# apollo4b register map
Vendor: Ambiq Micro; Series: Apollo; File version: 1.0
CPU: CM4 r1p0, little endian, MPU, FPU, I-cache, D-cache, VTOR, ITCM, DTCM, 3 interrupt priority bits, 0 interrupts
Registers are 32-bit, read-write, reset 0x0 unless marked. A register's access mark holds for its fields unless they carry their own. Offsets are from the block's base; [hi:lo] are bit positions; {n}, {i} and the like mark numbered series; 'fields as' and 'values as' point back to an identical list.

## GPIO (part 4 of 4) — General Purpose IO
Base 0x40010000
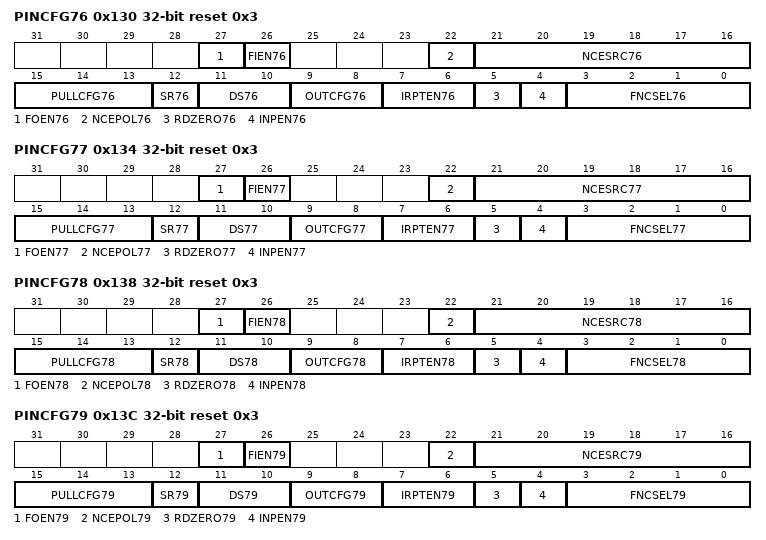
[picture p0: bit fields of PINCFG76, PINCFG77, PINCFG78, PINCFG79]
0x130 PINCFG76 reset 0x3 — Controls the operation of GPIO pin 76.
  [27] FOEN76 — Force output enable active regardless of function selected. Otherwise the selected function will enable the output only when needed
  [26] FIEN76 — Force input enable active regardless of function selected. Otherwise the selected function will enable the input only when needed
  [22] NCEPOL76 — Polarity select for NCE for GPIO 76
    0=LOW (Polarity is active low); 1=HIGH (Polarity is active high)
  [21:16] NCESRC76 — IOMSTR/MSPI N Chip Select 76, DISP control signals DE, CSX, and CS. Polarity is determined by CE_POLARITY field
    {v}=IOM0CE{v} (IOM 0 NCE {v} module) (v=0..3); {v}=IOM1CE{v-4} (IOM 1 NCE {v-4} module) (v=4..7); {v}=IOM2CE{v-8} (IOM 2 NCE {v-8} module) (v=8..11); {v}=IOM3CE{v-12} (IOM 3 NCE {v-12} module) (v=12..15); {v}=IOM4CE{v-16} (IOM 4 NCE {v-16} module) (v=16..19); {v}=IOM5CE{v-20} (IOM 5 NCE {v-20} module) (v=20..23); {v}=IOM6CE{v-24} (IOM 6 NCE {v-24} module) (v=24..27); {v}=IOM7CE{v-28} (IOM 7 NCE {v-28} module) (v=28..31); 32=MSPI0CEN0 (MSPI 0 NCE 0 module); 33=MSPI0CEN1 (MSPI 0 NCE 1 module); 34=MSPI1CEN0 (MSPI 1 NCE 0 module); 35=MSPI1CEN1 (MSPI 1 NCE 1 module); 36=MSPI2CEN0 (MSPI 2 NCE 0 module); 37=MSPI2CEN1 (MSPI 2 NCE 1 module); 38=DC_DPI_DE (DC DPI DE module); 39=DISP_CONT_CSX (DISP CONT CSX module); 40=DC_SPI_CS_N (DC SPI CS_N module); 41=DC_QSPI_CS_N (DC QSPI CS_N module); 42=DC_RESX (DC module RESX)
  [15:13] PULLCFG76 — Pullup/Pulldown configuration for GPIO 76
    0=DIS (No pullup or pulldown selected); 1=PD50K (50K Pulldown selected); 2=PU15K (1.5K Pullup selected); 3=PU6K (6K Pullup selected); 4=PU12K (12K Pullup selected); 5=PU24K (24K Pullup selected); 6=PU50K (50K Pullup selected); 7=PU100K (100K Pullup selected)
  [12] SR76 — Configure the slew rate
  [11:10] DS76 — Drive strength selection for GPIO 76
    0=0P1X (0.1x output driver selected); 1=0P5X (0.5x output driver selected); 2=0P75X (0.75x output driver selected); 3=1P0X (1.0x output driver selected)
  [9:8] OUTCFG76 — Pin IO mode selection for GPIO pin 76
    0=DIS (Output Disabled); 1=PUSHPULL (Output configured in push pull mode. Will drive 0 and 1 values on pin.); 2=OD (Output configured in open drain mode. Will only drive pin low, tristate otherwise.); 3=TS (Output configured in Tristate-able push pull mode. Will drive 0, 1 of HiZ on pin.)
  [7:6] IRPTEN76 — Interrupt enable for GPIO 76
    0=DIS (Interrupts are disabled for this GPIO); 1=INTFALL (Interrupts are enabled for falling edge transition on this GPIO); 2=INTRISE (Interrupts are enabled for rising edge transitions on this GPIO); 3=INTANY (Interrupts are enabled for any edge transition on this GPIO)
  [5] RDZERO76 — Return 0 for read data on GPIO 76
  [4] INPEN76 — Input enable for GPIO 76
  [3:0] FNCSEL76 — Function select for GPIO pin 76
    0=MSPI2_2 (MSPI Master 2 Interface Signal); 1=32KHzXT (32kHZ from analog); 2=DISP_QSPI_D2 (Display SPI Data2); 3=GPIO (General purpose I/O); 4=UART0RTS (UART Request to Send (RTS) (UART 0)); 5=DISP_D12 (Display Data 12); 6=CT76 (Timer/Counter input or output; Selection of direction is done via CTIMER register settings.); 7=NCE76 (IOMSTR/MSPI N Chip Select. Polarity is determined by CE_POLARITY field); 8=OBSBUS12 (Observation bus bit 12); 11=FPIO (Fast PIO)
0x134 PINCFG77 reset 0x3 — Controls the operation of GPIO pin 77.
  [27] FOEN77 — Force output enable active regardless of function selected. Otherwise the selected function will enable the output only when needed
  [26] FIEN77 — Force input enable active regardless of function selected. Otherwise the selected function will enable the input only when needed
  [22] NCEPOL77 — Polarity select for NCE for GPIO 77
    values as PINCFG76.NCEPOL76
  [21:16] NCESRC77 — IOMSTR/MSPI N Chip Select 77, DISP control signals DE, CSX, and CS. Polarity is determined by CE_POLARITY field
    values as PINCFG76.NCESRC76
  [15:13] PULLCFG77 — Pullup/Pulldown configuration for GPIO 77
    values as PINCFG76.PULLCFG76
  [12] SR77 — Configure the slew rate
  [11:10] DS77 — Drive strength selection for GPIO 77
    values as PINCFG76.DS76
  [9:8] OUTCFG77 — Pin IO mode selection for GPIO pin 77
    values as PINCFG76.OUTCFG76
  [7:6] IRPTEN77 — Interrupt enable for GPIO 77
    values as PINCFG76.IRPTEN76
  [5] RDZERO77 — Return 0 for read data on GPIO 77
  [4] INPEN77 — Input enable for GPIO 77
  [3:0] FNCSEL77 — Function select for GPIO pin 77
    0=MSPI2_3 (MSPI Master 2 Interface Signal); 2=DISP_QSPI_D3 (Display SPI Data3); 3=GPIO (General purpose I/O); 4=UART0CTS (UART Clear to Send (CTS) (UART 0)); 5=DISP_D13 (Display Data 13); 6=CT77 (Timer/Counter input or output; Selection of direction is done via CTIMER register settings.); 7=NCE77 (IOMSTR/MSPI N Chip Select. Polarity is determined by CE_POLARITY field); 8=OBSBUS13 (Observation bus bit 13); 11=FPIO (Fast PIO)
0x138 PINCFG78 reset 0x3 — Controls the operation of GPIO pin 78.
  [27] FOEN78 — Force output enable active regardless of function selected. Otherwise the selected function will enable the output only when needed
  [26] FIEN78 — Force input enable active regardless of function selected. Otherwise the selected function will enable the input only when needed
  [22] NCEPOL78 — Polarity select for NCE for GPIO 78
    values as PINCFG76.NCEPOL76
  [21:16] NCESRC78 — IOMSTR/MSPI N Chip Select 78, DISP control signals DE, CSX, and CS. Polarity is determined by CE_POLARITY field
    values as PINCFG76.NCESRC76
  [15:13] PULLCFG78 — Pullup/Pulldown configuration for GPIO 78
    values as PINCFG76.PULLCFG76
  [12] SR78 — Configure the slew rate
  [11:10] DS78 — Drive strength selection for GPIO 78
    values as PINCFG76.DS76
  [9:8] OUTCFG78 — Pin IO mode selection for GPIO pin 78
    values as PINCFG76.OUTCFG76
  [7:6] IRPTEN78 — Interrupt enable for GPIO 78
    values as PINCFG76.IRPTEN76
  [5] RDZERO78 — Return 0 for read data on GPIO 78
  [4] INPEN78 — Input enable for GPIO 78
  [3:0] FNCSEL78 — Function select for GPIO pin 78
    0=MSPI2_4 (MSPI Master 2 Interface Signal); 2=DISP_QSPI_SCK (Display SPI CLK); 3=GPIO (General purpose I/O); 4=UART0TX (UART transmit output (UART 0)); 5=DISP_D14 (Display Data 14); 6=CT78 (Timer/Counter input or output; Selection of direction is done via CTIMER register settings.); 7=NCE78 (IOMSTR/MSPI N Chip Select. Polarity is determined by CE_POLARITY field); 8=OBSBUS14 (Observation bus bit 14); 9=DISP_SPI_SCK (Display SPI Clock); 11=FPIO (Fast PIO)
0x13C PINCFG79 reset 0x3 — Controls the operation of GPIO pin 79.
  [27] FOEN79 — Force output enable active regardless of function selected. Otherwise the selected function will enable the output only when needed
  [26] FIEN79 — Force input enable active regardless of function selected. Otherwise the selected function will enable the input only when needed
  [22] NCEPOL79 — Polarity select for NCE for GPIO 79
    values as PINCFG76.NCEPOL76
  [21:16] NCESRC79 — IOMSTR/MSPI N Chip Select 79, DISP control signals DE, CSX, and CS. Polarity is determined by CE_POLARITY field
    values as PINCFG76.NCESRC76
  [15:13] PULLCFG79 — Pullup/Pulldown configuration for GPIO 79
    values as PINCFG76.PULLCFG76
  [12] SR79 — Configure the slew rate
  [11:10] DS79 — Drive strength selection for GPIO 79
    values as PINCFG76.DS76
  [9:8] OUTCFG79 — Pin IO mode selection for GPIO pin 79
    values as PINCFG76.OUTCFG76
  [7:6] IRPTEN79 — Interrupt enable for GPIO 79
    values as PINCFG76.IRPTEN76
  [5] RDZERO79 — Return 0 for read data on GPIO 79
  [4] INPEN79 — Input enable for GPIO 79
  [3:0] FNCSEL79 — Function select for GPIO pin 79
    0=MSPI2_5 (MSPI Master 2 Interface Signal); 2=SDIF_DAT4 (SD/SDIO/MMC Data4 pin); 3=GPIO (General purpose I/O); 4=SWO (Serial Wire Output); 5=DISP_VS (Display RGB VSYNC); 6=CT79 (Timer/Counter input or output; Selection of direction is done via CTIMER register settings.); 7=NCE79 (IOMSTR/MSPI N Chip Select. Polarity is determined by CE_POLARITY field); 8=OBSBUS15 (Observation bus bit 15); 9=DISP_SPI_SDI (Display SPI Data IN); 11=FPIO (Fast PIO)
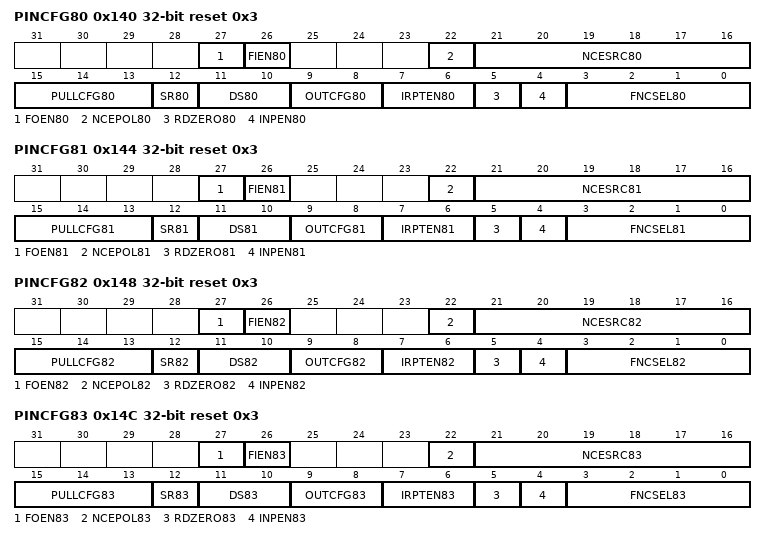
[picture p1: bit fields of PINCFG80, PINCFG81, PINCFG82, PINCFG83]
0x140 PINCFG80 reset 0x3 — Controls the operation of GPIO pin 80.
  [27] FOEN80 — Force output enable active regardless of function selected. Otherwise the selected function will enable the output only when needed
  [26] FIEN80 — Force input enable active regardless of function selected. Otherwise the selected function will enable the input only when needed
  [22] NCEPOL80 — Polarity select for NCE for GPIO 80
    values as PINCFG76.NCEPOL76
  [21:16] NCESRC80 — IOMSTR/MSPI N Chip Select 80, DISP control signals DE, CSX, and CS. Polarity is determined by CE_POLARITY field
    values as PINCFG76.NCESRC76
  [15:13] PULLCFG80 — Pullup/Pulldown configuration for GPIO 80
    values as PINCFG76.PULLCFG76
  [12] SR80 — Configure the slew rate
  [11:10] DS80 — Drive strength selection for GPIO 80
    values as PINCFG76.DS76
  [9:8] OUTCFG80 — Pin IO mode selection for GPIO pin 80
    values as PINCFG76.OUTCFG76
  [7:6] IRPTEN80 — Interrupt enable for GPIO 80
    values as PINCFG76.IRPTEN76
  [5] RDZERO80 — Return 0 for read data on GPIO 80
  [4] INPEN80 — Input enable for GPIO 80
  [3:0] FNCSEL80 — Function select for GPIO pin 80
    0=MSPI2_6 (MSPI Master 2 Interface Signal); 1=CLKOUT (Oscillator output clock); 2=SDIF_DAT5 (SD/SDIO/MMC Data5 pin); 3=GPIO (General purpose I/O); 4=SWTRACE0 (Serial Wire Debug Trace Output 0); 5=DISP_HS (Display RGB HSYNC); 6=CT80 (Timer/Counter input or output; Selection of direction is done via CTIMER register settings.); 7=NCE80 (IOMSTR/MSPI N Chip Select. Polarity is determined by CE_POLARITY field); 8=OBSBUS0 (Observation bus bit 0); 11=FPIO (Fast PIO)
0x144 PINCFG81 reset 0x3 — Controls the operation of GPIO pin 81.
  [27] FOEN81 — Force output enable active regardless of function selected. Otherwise the selected function will enable the output only when needed
  [26] FIEN81 — Force input enable active regardless of function selected. Otherwise the selected function will enable the input only when needed
  [22] NCEPOL81 — Polarity select for NCE for GPIO 81
    values as PINCFG76.NCEPOL76
  [21:16] NCESRC81 — IOMSTR/MSPI N Chip Select 81, DISP control signals DE, CSX, and CS. Polarity is determined by CE_POLARITY field
    values as PINCFG76.NCESRC76
  [15:13] PULLCFG81 — Pullup/Pulldown configuration for GPIO 81
    values as PINCFG76.PULLCFG76
  [12] SR81 — Configure the slew rate
  [11:10] DS81 — Drive strength selection for GPIO 81
    values as PINCFG76.DS76
  [9:8] OUTCFG81 — Pin IO mode selection for GPIO pin 81
    values as PINCFG76.OUTCFG76
  [7:6] IRPTEN81 — Interrupt enable for GPIO 81
    values as PINCFG76.IRPTEN76
  [5] RDZERO81 — Return 0 for read data on GPIO 81
  [4] INPEN81 — Input enable for GPIO 81
  [3:0] FNCSEL81 — Function select for GPIO pin 81
    0=MSPI2_7 (MSPI Master 2 Interface Signal); 1=CLKOUT (Oscillator output clock); 2=SDIF_DAT6 (SD/SDIO/MMC Data6 pin); 3=GPIO (General purpose I/O); 4=SWTRACE1 (Serial Wire Debug Trace Output 1); 5=DISP_DE (Display RGB Data Enable); 6=CT81 (Timer/Counter input or output; Selection of direction is done via CTIMER register settings.); 7=NCE81 (IOMSTR/MSPI N Chip Select. Polarity is determined by CE_POLARITY field); 8=OBSBUS1 (Observation bus bit 1); 11=FPIO (Fast PIO)
0x148 PINCFG82 reset 0x3 — Controls the operation of GPIO pin 82.
  [27] FOEN82 — Force output enable active regardless of function selected. Otherwise the selected function will enable the output only when needed
  [26] FIEN82 — Force input enable active regardless of function selected. Otherwise the selected function will enable the input only when needed
  [22] NCEPOL82 — Polarity select for NCE for GPIO 82
    values as PINCFG76.NCEPOL76
  [21:16] NCESRC82 — IOMSTR/MSPI N Chip Select 82, DISP control signals DE, CSX, and CS. Polarity is determined by CE_POLARITY field
    values as PINCFG76.NCESRC76
  [15:13] PULLCFG82 — Pullup/Pulldown configuration for GPIO 82
    values as PINCFG76.PULLCFG76
  [12] SR82 — Configure the slew rate
  [11:10] DS82 — Drive strength selection for GPIO 82
    values as PINCFG76.DS76
  [9:8] OUTCFG82 — Pin IO mode selection for GPIO pin 82
    values as PINCFG76.OUTCFG76
  [7:6] IRPTEN82 — Interrupt enable for GPIO 82
    values as PINCFG76.IRPTEN76
  [5] RDZERO82 — Return 0 for read data on GPIO 82
  [4] INPEN82 — Input enable for GPIO 82
  [3:0] FNCSEL82 — Function select for GPIO pin 82
    0=MSPI2_8 (MSPI Master 2 Interface Signal); 1=32KHzXT (32kHZ from analog); 2=SDIF_DAT7 (SD/SDIO/MMC Data7 pin); 3=GPIO (General purpose I/O); 4=SWTRACE2 (Serial Wire Debug Trace Output 2); 5=DISP_PCLK (Display RGB Pixel Clock); 6=CT82 (Timer/Counter input or output; Selection of direction is done via CTIMER register settings.); 7=NCE82 (IOMSTR/MSPI N Chip Select. Polarity is determined by CE_POLARITY field); 8=OBSBUS2 (Observation bus bit 2); 11=FPIO (Fast PIO)
0x14C PINCFG83 reset 0x3 — Controls the operation of GPIO pin 83.
  [27] FOEN83 — Force output enable active regardless of function selected. Otherwise the selected function will enable the output only when needed
  [26] FIEN83 — Force input enable active regardless of function selected. Otherwise the selected function will enable the input only when needed
  [22] NCEPOL83 — Polarity select for NCE for GPIO 83
    values as PINCFG76.NCEPOL76
  [21:16] NCESRC83 — IOMSTR/MSPI N Chip Select 83, DISP control signals DE, CSX, and CS. Polarity is determined by CE_POLARITY field
    values as PINCFG76.NCESRC76
  [15:13] PULLCFG83 — Pullup/Pulldown configuration for GPIO 83
    values as PINCFG76.PULLCFG76
  [12] SR83 — Configure the slew rate
  [11:10] DS83 — Drive strength selection for GPIO 83
    values as PINCFG76.DS76
  [9:8] OUTCFG83 — Pin IO mode selection for GPIO pin 83
    values as PINCFG76.OUTCFG76
  [7:6] IRPTEN83 — Interrupt enable for GPIO 83
    values as PINCFG76.IRPTEN76
  [5] RDZERO83 — Return 0 for read data on GPIO 83
  [4] INPEN83 — Input enable for GPIO 83
  [3:0] FNCSEL83 — Function select for GPIO pin 83
    0=MSPI2_9 (MSPI Master 2 Interface Signal); 1=32KHzXT (32kHZ from analog); 2=SDIF_CMD (SD1/SD4/MMC Command pin); 3=GPIO (General purpose I/O); 4=SWTRACE3 (Serial Wire Debug Trace Output 3); 5=DISP_SD (Display RGB Shutdown); 6=CT83 (Timer/Counter input or output; Selection of direction is done via CTIMER register settings.); 7=NCE83 (IOMSTR/MSPI N Chip Select. Polarity is determined by CE_POLARITY field); 8=OBSBUS3 (Observation bus bit 3); 11=FPIO (Fast PIO)
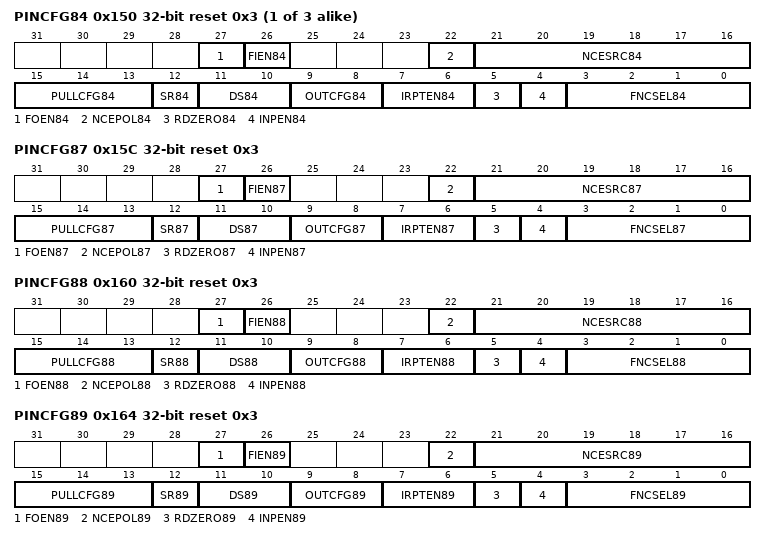
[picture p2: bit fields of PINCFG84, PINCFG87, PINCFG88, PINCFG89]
{0x0+4i} PINCFG{i} reset 0x3 (i=84..86) — Controls the operation of GPIO pin {i}.
  [27] FOEN{i} — Force output enable active regardless of function selected. Otherwise the selected function will enable the output only when needed
  [26] FIEN{i} — Force input enable active regardless of function selected. Otherwise the selected function will enable the input only when needed
  [22] NCEPOL{i} — Polarity select for NCE for GPIO {i}
    values as PINCFG76.NCEPOL76
  [21:16] NCESRC{i} — IOMSTR/MSPI N Chip Select {i}, DISP control signals DE, CSX, and CS. Polarity is determined by CE_POLARITY field
    values as PINCFG76.NCESRC76
  [15:13] PULLCFG{i} — Pullup/Pulldown configuration for GPIO {i}
    values as PINCFG76.PULLCFG76
  [12] SR{i} — Configure the slew rate
  [11:10] DS{i} — Drive strength selection for GPIO {i}
    values as PINCFG76.DS76
  [9:8] OUTCFG{i} — Pin IO mode selection for GPIO pin {i}
    values as PINCFG76.OUTCFG76
  [7:6] IRPTEN{i} — Interrupt enable for GPIO {i}
    values as PINCFG76.IRPTEN76
  [5] RDZERO{i} — Return 0 for read data on GPIO {i}
  [4] INPEN{i} — Input enable for GPIO {i}
  [3:0] FNCSEL{i} — Function select for GPIO pin {i}
    2=SDIF_DAT{i-84} (SD/SDIO/MMC Data{i-84} pin); 3=GPIO (General purpose I/O); 6=CT{i} (Timer/Counter input or output; Selection of direction is done via CTIMER register settings.); 7=NCE{i} (IOMSTR/MSPI N Chip Select. Polarity is determined by CE_POLARITY field); 8=OBSBUS{i-80} (Observation bus bit {i-80}); 11=FPIO (Fast PIO)
0x15C PINCFG87 reset 0x3 — Controls the operation of GPIO pin 87.
  [27] FOEN87 — Force output enable active regardless of function selected. Otherwise the selected function will enable the output only when needed
  [26] FIEN87 — Force input enable active regardless of function selected. Otherwise the selected function will enable the input only when needed
  [22] NCEPOL87 — Polarity select for NCE for GPIO 87
    values as PINCFG76.NCEPOL76
  [21:16] NCESRC87 — IOMSTR/MSPI N Chip Select 87, DISP control signals DE, CSX, and CS. Polarity is determined by CE_POLARITY field
    values as PINCFG76.NCESRC76
  [15:13] PULLCFG87 — Pullup/Pulldown configuration for GPIO 87
    values as PINCFG76.PULLCFG76
  [12] SR87 — Configure the slew rate
  [11:10] DS87 — Drive strength selection for GPIO 87
    values as PINCFG76.DS76
  [9:8] OUTCFG87 — Pin IO mode selection for GPIO pin 87
    values as PINCFG76.OUTCFG76
  [7:6] IRPTEN87 — Interrupt enable for GPIO 87
    values as PINCFG76.IRPTEN76
  [5] RDZERO87 — Return 0 for read data on GPIO 87
  [4] INPEN87 — Input enable for GPIO 87
  [3:0] FNCSEL87 — Function select for GPIO pin 87
    2=SDIF_DAT3 (SD/SDIO/MMC Data3 pin); 3=GPIO (General purpose I/O); 6=CT87 (Timer/Counter input or output; Selection of direction is done via CTIMER register settings.); 7=NCE87 (IOMSTR/MSPI N Chip Select. Polarity is determined by CE_POLARITY field); 8=OBSBUS7 (Observation bus bit 7); 9=DISP_TE (Display TE input); 11=FPIO (Fast PIO)
0x160 PINCFG88 reset 0x3 — Controls the operation of GPIO pin 88.
  [27] FOEN88 — Force output enable active regardless of function selected. Otherwise the selected function will enable the output only when needed
  [26] FIEN88 — Force input enable active regardless of function selected. Otherwise the selected function will enable the input only when needed
  [22] NCEPOL88 — Polarity select for NCE for GPIO 88
    values as PINCFG76.NCEPOL76
  [21:16] NCESRC88 — IOMSTR/MSPI N Chip Select 88, DISP control signals DE, CSX, and CS. Polarity is determined by CE_POLARITY field
    values as PINCFG76.NCESRC76
  [15:13] PULLCFG88 — Pullup/Pulldown configuration for GPIO 88
    values as PINCFG76.PULLCFG76
  [12] SR88 — Configure the slew rate
  [11:10] DS88 — Drive strength selection for GPIO 88
    values as PINCFG76.DS76
  [9:8] OUTCFG88 — Pin IO mode selection for GPIO pin 88
    values as PINCFG76.OUTCFG76
  [7:6] IRPTEN88 — Interrupt enable for GPIO 88
    values as PINCFG76.IRPTEN76
  [5] RDZERO88 — Return 0 for read data on GPIO 88
  [4] INPEN88 — Input enable for GPIO 88
  [3:0] FNCSEL88 — Function select for GPIO pin 88
    2=SDIF_CLKOUT (SD/SDIO/MMC Clock to Card (CLK)); 3=GPIO (General purpose I/O); 6=CT88 (Timer/Counter input or output; Selection of direction is done via CTIMER register settings.); 7=NCE88 (IOMSTR/MSPI N Chip Select. Polarity is determined by CE_POLARITY field); 8=OBSBUS8 (Observation bus bit 8); 11=FPIO (Fast PIO)
0x164 PINCFG89 reset 0x3 — Controls the operation of GPIO pin 89.
  [27] FOEN89 — Force output enable active regardless of function selected. Otherwise the selected function will enable the output only when needed
  [26] FIEN89 — Force input enable active regardless of function selected. Otherwise the selected function will enable the input only when needed
  [22] NCEPOL89 — Polarity select for NCE for GPIO 89
    values as PINCFG76.NCEPOL76
  [21:16] NCESRC89 — IOMSTR/MSPI N Chip Select 89, DISP control signals DE, CSX, and CS. Polarity is determined by CE_POLARITY field
    values as PINCFG76.NCESRC76
  [15:13] PULLCFG89 — Pullup/Pulldown configuration for GPIO 89
    values as PINCFG76.PULLCFG76
  [12] SR89 — Configure the slew rate
  [11:10] DS89 — Drive strength selection for GPIO 89
    0=0P1X (0.1x output driver selected); 1=0P5X (0.5x output driver selected)
  [9:8] OUTCFG89 — Pin IO mode selection for GPIO pin 89
    values as PINCFG76.OUTCFG76
  [7:6] IRPTEN89 — Interrupt enable for GPIO 89
    values as PINCFG76.IRPTEN76
  [5] RDZERO89 — Return 0 for read data on GPIO 89
  [4] INPEN89 — Input enable for GPIO 89
  [3:0] FNCSEL89 — Function select for GPIO pin 89
    3=GPIO (General purpose I/O); 5=DISP_CM (Display RGB Color Mode); 6=CT89 (Timer/Counter input or output; Selection of direction is done via CTIMER register settings.); 7=NCE89 (IOMSTR/MSPI N Chip Select. Polarity is determined by CE_POLARITY field); 8=OBSBUS9 (Observation bus bit 9); 11=FPIO (Fast PIO)
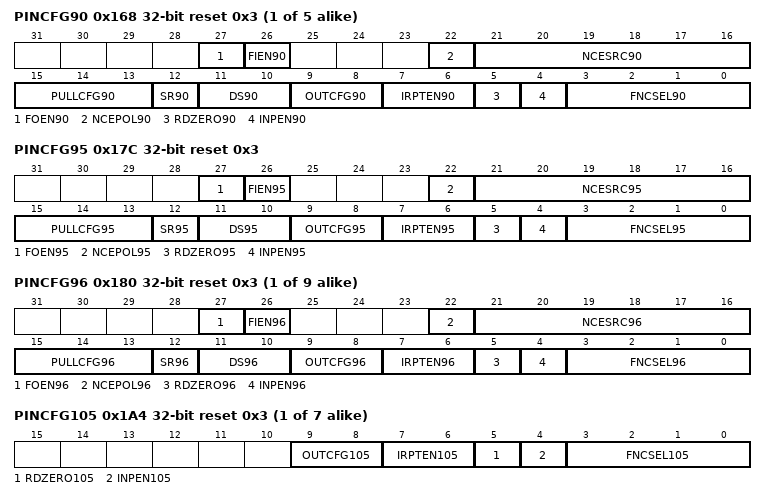
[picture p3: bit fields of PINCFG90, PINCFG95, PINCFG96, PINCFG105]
{0x0+4i} PINCFG{i} reset 0x3 (i=90..94) — Controls the operation of GPIO pin {i}.
  [27] FOEN{i} — Force output enable active regardless of function selected. Otherwise the selected function will enable the output only when needed
  [26] FIEN{i} — Force input enable active regardless of function selected. Otherwise the selected function will enable the input only when needed
  [22] NCEPOL{i} — Polarity select for NCE for GPIO {i}
    values as PINCFG76.NCEPOL76
  [21:16] NCESRC{i} — IOMSTR/MSPI N Chip Select {i}, DISP control signals DE, CSX, and CS. Polarity is determined by CE_POLARITY field
    values as PINCFG76.NCESRC76
  [15:13] PULLCFG{i} — Pullup/Pulldown configuration for GPIO {i}
    values as PINCFG76.PULLCFG76
  [12] SR{i} — Configure the slew rate
  [11:10] DS{i} — Drive strength selection for GPIO {i}
    values as PINCFG89.DS89
  [9:8] OUTCFG{i} — Pin IO mode selection for GPIO pin {i}
    values as PINCFG76.OUTCFG76
  [7:6] IRPTEN{i} — Interrupt enable for GPIO {i}
    values as PINCFG76.IRPTEN76
  [5] RDZERO{i} — Return 0 for read data on GPIO {i}
  [4] INPEN{i} — Input enable for GPIO {i}
  [3:0] FNCSEL{i} — Function select for GPIO pin {i}
    3=GPIO (General purpose I/O); 6=CT{i} (Timer/Counter input or output; Selection of direction is done via CTIMER register settings.); 7=NCE{i} (IOMSTR/MSPI N Chip Select. Polarity is determined by CE_POLARITY field); 8=OBSBUS{i-80} (Observation bus bit {i-80}); 9=VCMPO (Output of the voltage comparator signal); 11=FPIO (Fast PIO)
0x17C PINCFG95 reset 0x3 — Controls the operation of GPIO pin 95.
  [27] FOEN95 — Force output enable active regardless of function selected. Otherwise the selected function will enable the output only when needed
  [26] FIEN95 — Force input enable active regardless of function selected. Otherwise the selected function will enable the input only when needed
  [22] NCEPOL95 — Polarity select for NCE for GPIO 95
    values as PINCFG76.NCEPOL76
  [21:16] NCESRC95 — IOMSTR/MSPI N Chip Select 95, DISP control signals DE, CSX, and CS. Polarity is determined by CE_POLARITY field
    values as PINCFG76.NCESRC76
  [15:13] PULLCFG95 — Pullup/Pulldown configuration for GPIO 95
    values as PINCFG76.PULLCFG76
  [12] SR95 — Configure the slew rate
  [11:10] DS95 — Drive strength selection for GPIO 95
    values as PINCFG89.DS89
  [9:8] OUTCFG95 — Pin IO mode selection for GPIO pin 95
    values as PINCFG76.OUTCFG76
  [7:6] IRPTEN95 — Interrupt enable for GPIO 95
    values as PINCFG76.IRPTEN76
  [5] RDZERO95 — Return 0 for read data on GPIO 95
  [4] INPEN95 — Input enable for GPIO 95
  [3:0] FNCSEL95 — Function select for GPIO pin 95
    3=GPIO (General purpose I/O); 6=CT95 (Timer/Counter input or output; Selection of direction is done via CTIMER register settings.); 7=NCE95 (IOMSTR/MSPI N Chip Select. Polarity is determined by CE_POLARITY field); 8=OBSBUS15 (Observation bus bit 15); 11=FPIO (Fast PIO)
{0x0+4i} PINCFG{i} reset 0x3 (i=96..104) — Controls the operation of GPIO pin {i}.
  [27] FOEN{i} — Force output enable active regardless of function selected. Otherwise the selected function will enable the output only when needed
  [26] FIEN{i} — Force input enable active regardless of function selected. Otherwise the selected function will enable the input only when needed
  [22] NCEPOL{i} — Polarity select for NCE for GPIO {i}
    values as PINCFG76.NCEPOL76
  [21:16] NCESRC{i} — IOMSTR/MSPI N Chip Select {i}, DISP control signals DE, CSX, and CS. Polarity is determined by CE_POLARITY field
    values as PINCFG76.NCESRC76
  [15:13] PULLCFG{i} — Pullup/Pulldown configuration for GPIO {i}
    values as PINCFG76.PULLCFG76
  [12] SR{i} — Configure the slew rate
  [11:10] DS{i} — Drive strength selection for GPIO {i}
    values as PINCFG89.DS89
  [9:8] OUTCFG{i} — Pin IO mode selection for GPIO pin {i}
    values as PINCFG76.OUTCFG76
  [7:6] IRPTEN{i} — Interrupt enable for GPIO {i}
    values as PINCFG76.IRPTEN76
  [5] RDZERO{i} — Return 0 for read data on GPIO {i}
  [4] INPEN{i} — Input enable for GPIO {i}
  [3:0] FNCSEL{i} — Function select for GPIO pin {i}
    3=GPIO (General purpose I/O); 6=CT{i} (Timer/Counter input or output; Selection of direction is done via CTIMER register settings.); 7=NCE{i} (IOMSTR/MSPI N Chip Select. Polarity is determined by CE_POLARITY field); 8=OBSBUS{i-96} (Observation bus bit {i-96}); 11=FPIO (Fast PIO)
{0x0+4i} PINCFG{i} reset 0x3 (i=105..111) — Controls the operation of virtual GPIO pin {i}.
  [9:8] OUTCFG{i} — Pin IO mode selection for GPIO pin {i}
    values as PINCFG76.OUTCFG76
  [7:6] IRPTEN{i} — Interrupt enable for GPIO {i}
    values as PINCFG76.IRPTEN76
  [5] RDZERO{i} — Return 0 for read data on GPIO {i}
  [4] INPEN{i} — Input enable for GPIO {i}
  [3:0] FNCSEL{i} — Function select for GPIO pin {i}
    3=GPIO (General purpose I/O); 6=CT{i} (Timer/Counter input or output; Selection of direction is done via CTIMER register settings.); 8=OBSBUS{i-96} (Observation bus bit {i-96})
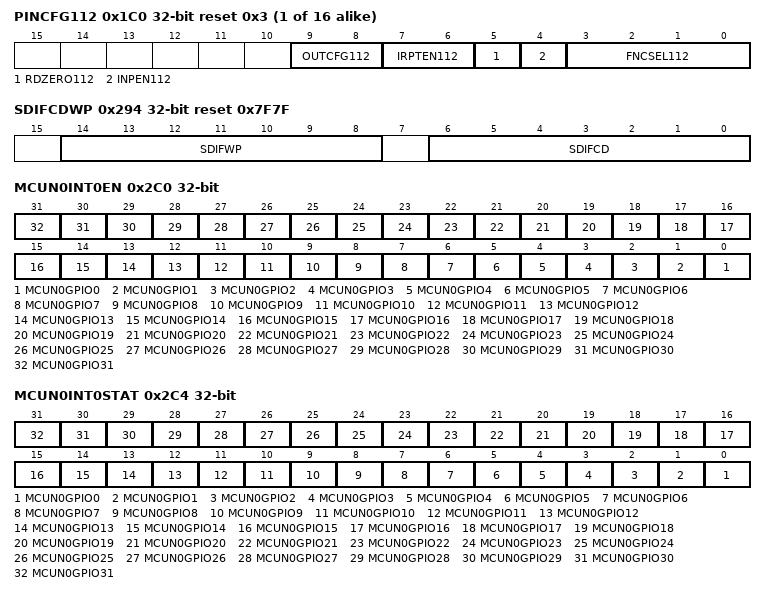
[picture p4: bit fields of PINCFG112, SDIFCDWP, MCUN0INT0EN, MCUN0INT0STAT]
{0x0+4i} PINCFG{i} reset 0x3 (i=112..127) — Controls the operation of virtual GPIO pin {i}.
  [9:8] OUTCFG{i} — Pin IO mode selection for GPIO pin {i}
    values as PINCFG76.OUTCFG76
  [7:6] IRPTEN{i} — Interrupt enable for GPIO {i}
    values as PINCFG76.IRPTEN76
  [5] RDZERO{i} — Return 0 for read data on GPIO {i}
  [4] INPEN{i} — Input enable for GPIO {i}
  [3:0] FNCSEL{i} — Function select for GPIO pin {i}
    3=GPIO (General purpose I/O); 6=CT{i} (Timer/Counter input or output; Selection of direction is done via CTIMER register settings.); 8=OBSBUS{i-112} (Observation bus bit {i-112})
0x200 PADKEY — Lock state of the PINCFG and GPIO configuration registers. Write a value of 0x73 to unlock write access to the PAD and GPIO.
  [31:0] PADKEY — Key register value.
    115=Key (Key value to unlock the register.)
{0x204+4i} RD{i} (i=0..3) — GPIO Input {i} ({32i+31}-{32i})
  [31:0] RD{i} — GPIO{32i+31}-{32i} Reads pin state - read only. Returns the pad pin state for pins 0-31 if the PINCFG's input enable (INPEN) is active and RDZERO is inactive.
{0x214+4i} WT{i} (i=0..3) — GPIO Output {i} ({32i+31}-{32i})
  [31:0] WT{i} — GPIO{32i+31}-{32i} Reads or writes pin state. Writes of 1 bits set output pad signal if the GPIO is enabled for output. Reads return status, including sets/clears through the WTS and WTC registers.
{0x224+4i} WTS{i} (i=0..3) — GPIO Output Set {i} ({32i+31}-{32i})
  [31:0] WTS{i} — GPIO{32i+31}-{32i} Sets pin state. Writing a 1 to any bit sets the corresponding bit in the WT register if the GPIO is enabled for output. Writing a value of 0 has no effect on the corresponding bit in the WT register. Status reads should be made via the WT Register.
{0x234+4i} WTC{i} (i=0..3) — GPIO Output Clear {i} ({32i+31}-{32i})
  [31:0] WTC{i} — GPIO{32i+31}-{32i} Clears pin state. Writing a 1 to any bit clears the corresponding bit in the WT register if the GPIO is enabled for output. Writing a value of 0 has no effect on the corresponding bit in the WT register. Status reads should be made via the WT register.
{0x244+4i} EN{i} (i=0..3) — GPIO Enable {i} ({32i+31}-{32i})
  [31:0] EN{i} — GPIO{32i+31}-{32i} Enables tri-state pin output. Writing a 1 to any bit enables, and writing a 0 to any bit disables, the output for the corresponding GPIO. Reads return output enable/disable status of GPIO.
{0x254+4i} ENS{i} (i=0..3) — GPIO Enable Set {i} ({32i+31}-{32i})
  [31:0] ENS{i} — GPIO{32i+31}-{32i} Sets pin tri-state output enables. Writing a 1 to any bit sets the corresponding bit in the EN register. Writing a value of 0 has no effect on the corresponding bit in the EN register. Status reads should be made to the EN Register.
{0x264+4i} ENC{i} (i=0..3) — GPIO Enable Clear {i} ({32i+31}-{32i})
  [31:0] ENC{i} — GPIO{32i+31}-{32i} Clears pin tri-state output enables. Writing a 1 to any bit clears the corresponding bit in the EN register. Writing a value of 0 has no effect on the corresponding bit in the EN register. Status reads should be made to the EN Register.
0x274 IOM0IRQ reset 0x7F — IOM0 IRQ select for flow control.
  [6:0] IOM0IRQ — IOM0 IRQ pad select.
{0x274+4i} IOM{i}IRQ reset 0x3F (i=1..7) — IOM{i} IRQ select for flow control.
  [6:0] IOM{i}IRQ — IOM{i} IRQ pad select.
0x294 SDIFCDWP reset 0x7F7F — SDIF CD and WP Select.
  [14:8] SDIFWP — SDIF WP pad select.
  [6:0] SDIFCD — SDIF CD pad select.
0x298 OBSDATA — GPIO Observation mode sample
  [15:0] OBSDATA — Sample of the data output on the GPIO observation port. May have async sampling issues, as the data is not synronized to the read operation. Intended for debug purposes only.
{0x29C+4i} IEOBS{i} (i=0..3) — Read only. Reflects the value of the input enable signals for pads {32i+31}-{32i} sent to the pad.
  [31:0] IEDATA{i} — 1 indicates the input_en is active and the value of the pad will be trasmitted to the internal logic within the device.
{0x2AC+4i} OEOBS{i} (i=0..3) — Read only. Reflects the value of the output enable signals for pads {32i+31}-{32i} sent to the pad.
  [31:0] OEDATA{i} — The signal is negative active, and a value of 0 indicates the output_en_ is active and the MCU will be driving the pad.
0x2C0 MCUN0INT0EN — Set bits in this register to allow this module to generate the corresponding interrupt.
  [n] MCUN0GPIO{n} (n=0..31) — GPIO{n} MCU N0-priority interrupt.
0x2C4 MCUN0INT0STAT — Read bits from this register to discover the cause of a recent interrupt.
  [n] MCUN0GPIO{n} (n=0..31) — GPIO{n} MCU N0-priority interrupt.
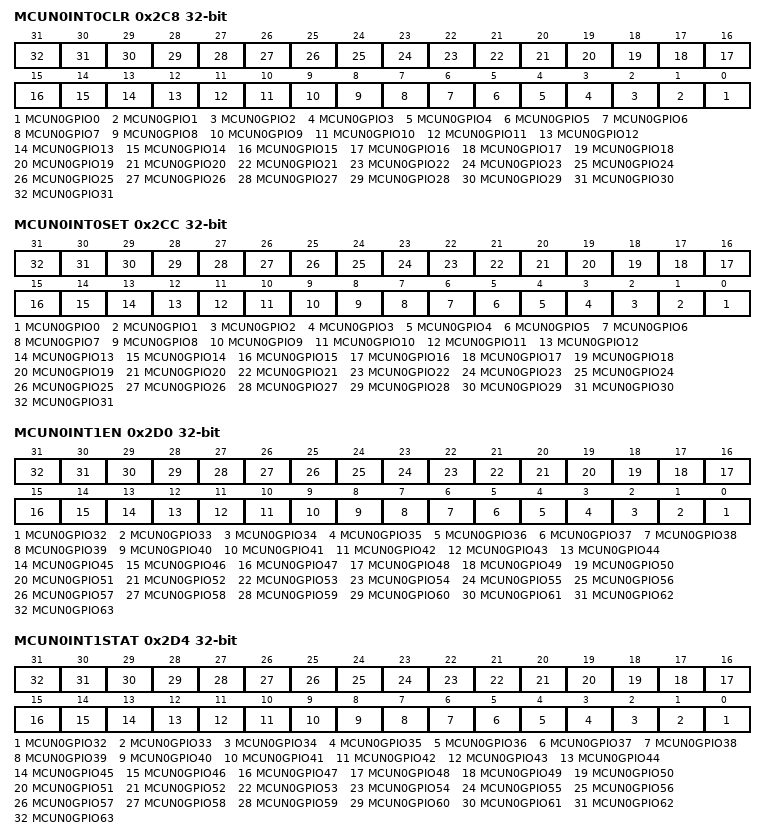
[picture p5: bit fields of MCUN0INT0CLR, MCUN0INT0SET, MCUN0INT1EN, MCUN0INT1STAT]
0x2C8 MCUN0INT0CLR — Write a 1 to a bit in this register to clear the interrupt status associated with that bit.
  [n] MCUN0GPIO{n} (n=0..31) — GPIO{n} MCU N0-priority interrupt.
0x2CC MCUN0INT0SET — Write a 1 to a bit in this register to instantly generate an interrupt from this module. (Generally used for testing purposes).
  [n] MCUN0GPIO{n} (n=0..31) — GPIO{n} MCU N0-priority interrupt.
0x2D0 MCUN0INT1EN — Set bits in this register to allow this module to generate the corresponding interrupt.
  [n-32] MCUN0GPIO{n} (n=32..63) — GPIO{n} MCU N0-priority interrupt.
0x2D4 MCUN0INT1STAT — Read bits from this register to discover the cause of a recent interrupt.
  [n-32] MCUN0GPIO{n} (n=32..63) — GPIO{n} MCU N0-priority interrupt.
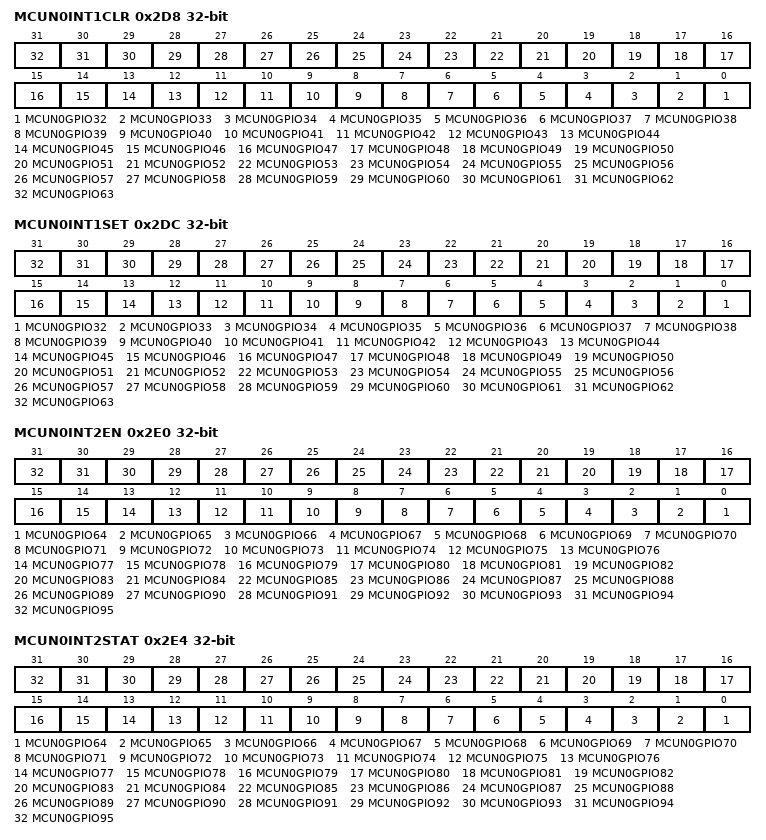
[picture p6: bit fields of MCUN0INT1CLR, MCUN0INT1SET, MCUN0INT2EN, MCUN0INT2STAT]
0x2D8 MCUN0INT1CLR — Write a 1 to a bit in this register to clear the interrupt status associated with that bit.
  [n-32] MCUN0GPIO{n} (n=32..63) — GPIO{n} MCU N0-priority interrupt.
0x2DC MCUN0INT1SET — Write a 1 to a bit in this register to instantly generate an interrupt from this module. (Generally used for testing purposes).
  [n-32] MCUN0GPIO{n} (n=32..63) — GPIO{n} MCU N0-priority interrupt.
0x2E0 MCUN0INT2EN — Set bits in this register to allow this module to generate the corresponding interrupt.
  [n-64] MCUN0GPIO{n} (n=64..95) — GPIO{n} MCU N0-priority interrupt.
0x2E4 MCUN0INT2STAT — Read bits from this register to discover the cause of a recent interrupt.
  [n-64] MCUN0GPIO{n} (n=64..95) — GPIO{n} MCU N0-priority interrupt.
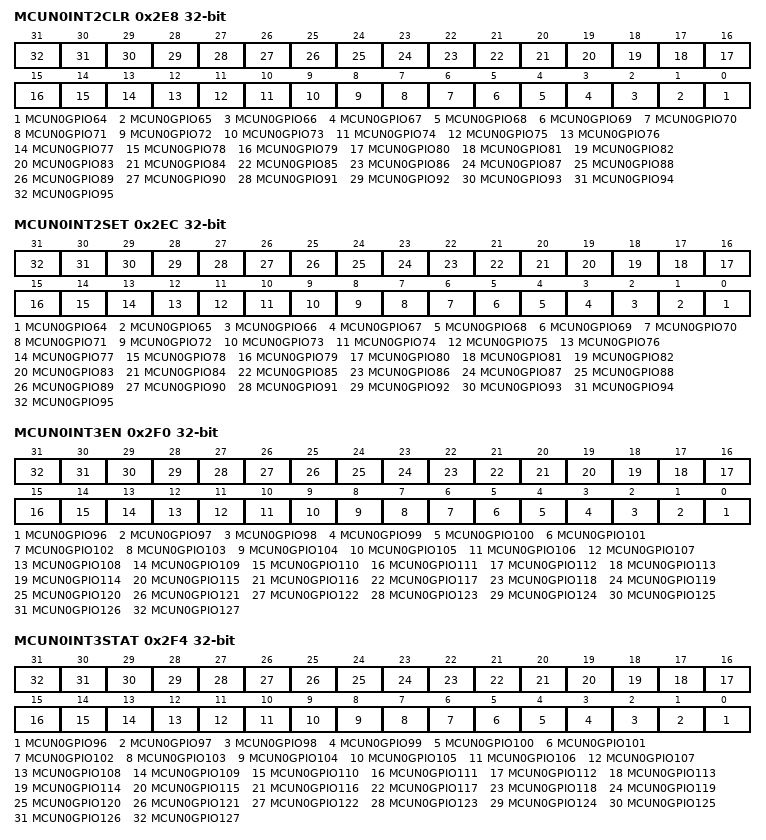
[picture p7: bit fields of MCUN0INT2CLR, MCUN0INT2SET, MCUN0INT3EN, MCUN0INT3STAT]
0x2E8 MCUN0INT2CLR — Write a 1 to a bit in this register to clear the interrupt status associated with that bit.
  [n-64] MCUN0GPIO{n} (n=64..95) — GPIO{n} MCU N0-priority interrupt.
0x2EC MCUN0INT2SET — Write a 1 to a bit in this register to instantly generate an interrupt from this module. (Generally used for testing purposes).
  [n-64] MCUN0GPIO{n} (n=64..95) — GPIO{n} MCU N0-priority interrupt.
0x2F0 MCUN0INT3EN — Set bits in this register to allow this module to generate the corresponding interrupt.
  [n-96] MCUN0GPIO{n} (n=96..127) — GPIO{n} MCU N0-priority interrupt.
0x2F4 MCUN0INT3STAT — Read bits from this register to discover the cause of a recent interrupt.
  [n-96] MCUN0GPIO{n} (n=96..127) — GPIO{n} MCU N0-priority interrupt.
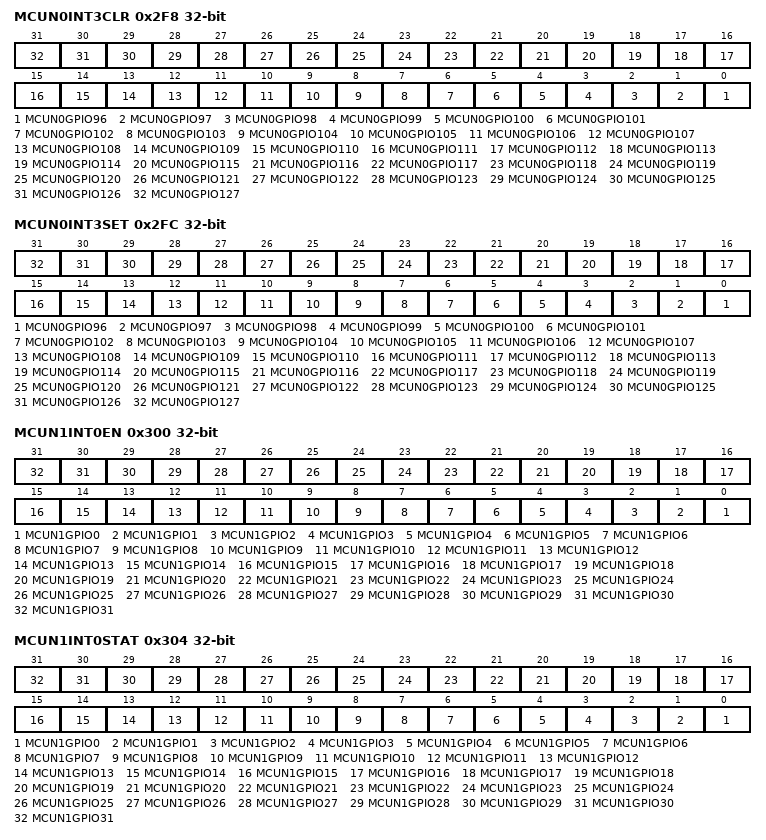
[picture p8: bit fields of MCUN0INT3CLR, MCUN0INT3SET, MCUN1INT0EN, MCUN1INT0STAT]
0x2F8 MCUN0INT3CLR — Write a 1 to a bit in this register to clear the interrupt status associated with that bit.
  [n-96] MCUN0GPIO{n} (n=96..127) — GPIO{n} MCU N0-priority interrupt.
0x2FC MCUN0INT3SET — Write a 1 to a bit in this register to instantly generate an interrupt from this module. (Generally used for testing purposes).
  [n-96] MCUN0GPIO{n} (n=96..127) — GPIO{n} MCU N0-priority interrupt.
0x300 MCUN1INT0EN — Set bits in this register to allow this module to generate the corresponding interrupt.
  [n] MCUN1GPIO{n} (n=0..31) — GPIO{n} MCU N1-priority interrupt.
0x304 MCUN1INT0STAT — Read bits from this register to discover the cause of a recent interrupt.
  [n] MCUN1GPIO{n} (n=0..31) — GPIO{n} MCU N1-priority interrupt.
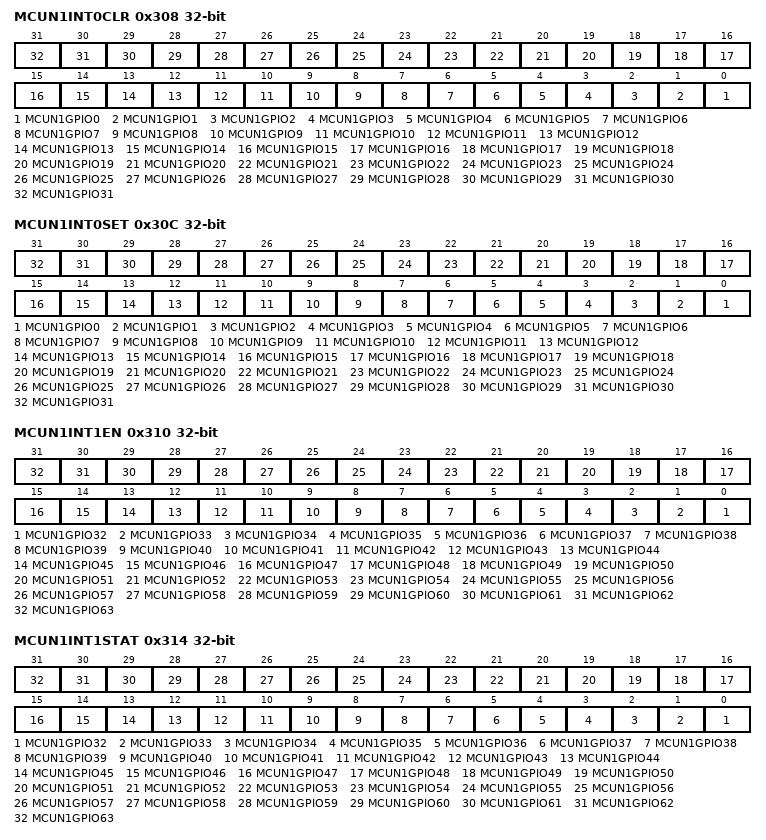
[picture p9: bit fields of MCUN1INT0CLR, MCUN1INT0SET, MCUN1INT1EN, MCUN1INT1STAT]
0x308 MCUN1INT0CLR — Write a 1 to a bit in this register to clear the interrupt status associated with that bit.
  [n] MCUN1GPIO{n} (n=0..31) — GPIO{n} MCU N1-priority interrupt.
0x30C MCUN1INT0SET — Write a 1 to a bit in this register to instantly generate an interrupt from this module. (Generally used for testing purposes).
  [n] MCUN1GPIO{n} (n=0..31) — GPIO{n} MCU N1-priority interrupt.
0x310 MCUN1INT1EN — Set bits in this register to allow this module to generate the corresponding interrupt.
  [n-32] MCUN1GPIO{n} (n=32..63) — GPIO{n} MCU N1-priority interrupt.
0x314 MCUN1INT1STAT — Read bits from this register to discover the cause of a recent interrupt.
  [n-32] MCUN1GPIO{n} (n=32..63) — GPIO{n} MCU N1-priority interrupt.
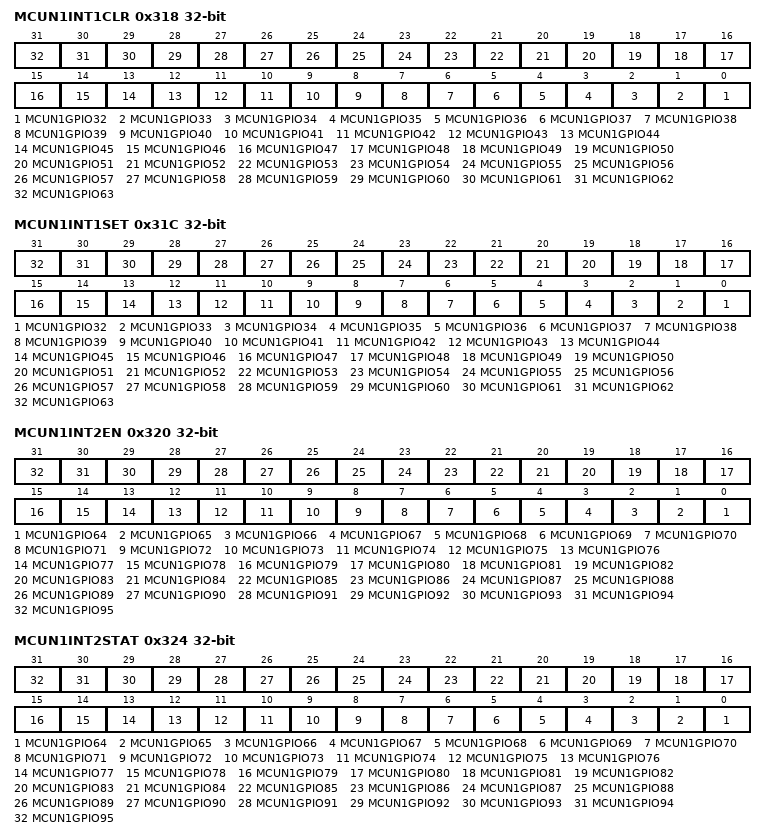
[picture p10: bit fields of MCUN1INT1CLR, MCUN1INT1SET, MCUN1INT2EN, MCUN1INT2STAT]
0x318 MCUN1INT1CLR — Write a 1 to a bit in this register to clear the interrupt status associated with that bit.
  [n-32] MCUN1GPIO{n} (n=32..63) — GPIO{n} MCU N1-priority interrupt.
0x31C MCUN1INT1SET — Write a 1 to a bit in this register to instantly generate an interrupt from this module. (Generally used for testing purposes).
  [n-32] MCUN1GPIO{n} (n=32..63) — GPIO{n} MCU N1-priority interrupt.
0x320 MCUN1INT2EN — Set bits in this register to allow this module to generate the corresponding interrupt.
  [n-64] MCUN1GPIO{n} (n=64..95) — GPIO{n} MCU N1-priority interrupt.
0x324 MCUN1INT2STAT — Read bits from this register to discover the cause of a recent interrupt.
  [n-64] MCUN1GPIO{n} (n=64..95) — GPIO{n} MCU N1-priority interrupt.
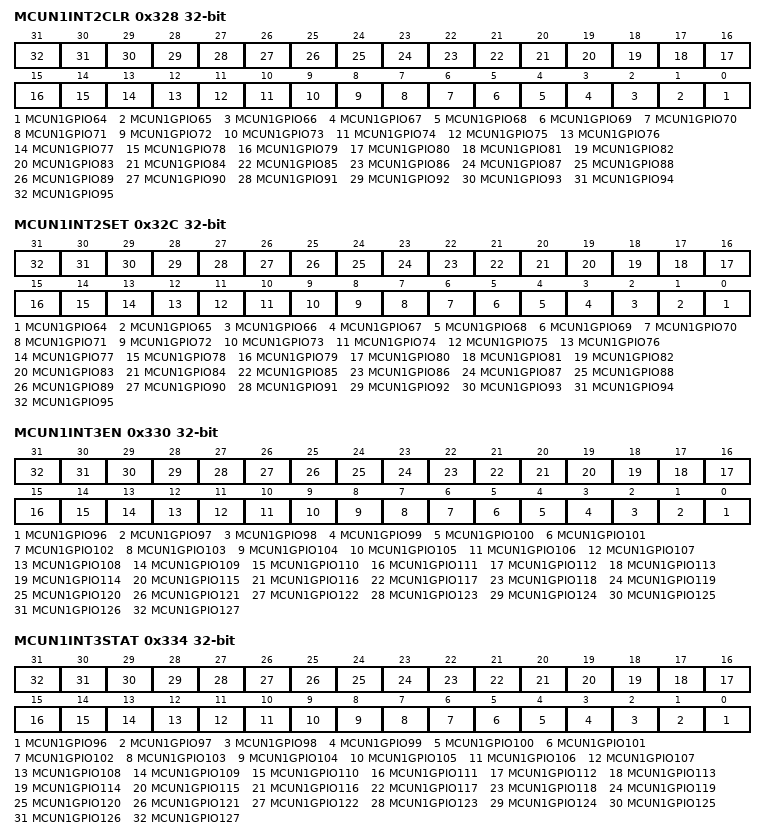
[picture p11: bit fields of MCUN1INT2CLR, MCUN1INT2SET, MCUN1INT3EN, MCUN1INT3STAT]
0x328 MCUN1INT2CLR — Write a 1 to a bit in this register to clear the interrupt status associated with that bit.
  [n-64] MCUN1GPIO{n} (n=64..95) — GPIO{n} MCU N1-priority interrupt.
0x32C MCUN1INT2SET — Write a 1 to a bit in this register to instantly generate an interrupt from this module. (Generally used for testing purposes).
  [n-64] MCUN1GPIO{n} (n=64..95) — GPIO{n} MCU N1-priority interrupt.
0x330 MCUN1INT3EN — Set bits in this register to allow this module to generate the corresponding interrupt.
  [n-96] MCUN1GPIO{n} (n=96..127) — GPIO{n} MCU N1-priority interrupt.
0x334 MCUN1INT3STAT — Read bits from this register to discover the cause of a recent interrupt.
  [n-96] MCUN1GPIO{n} (n=96..127) — GPIO{n} MCU N1-priority interrupt.
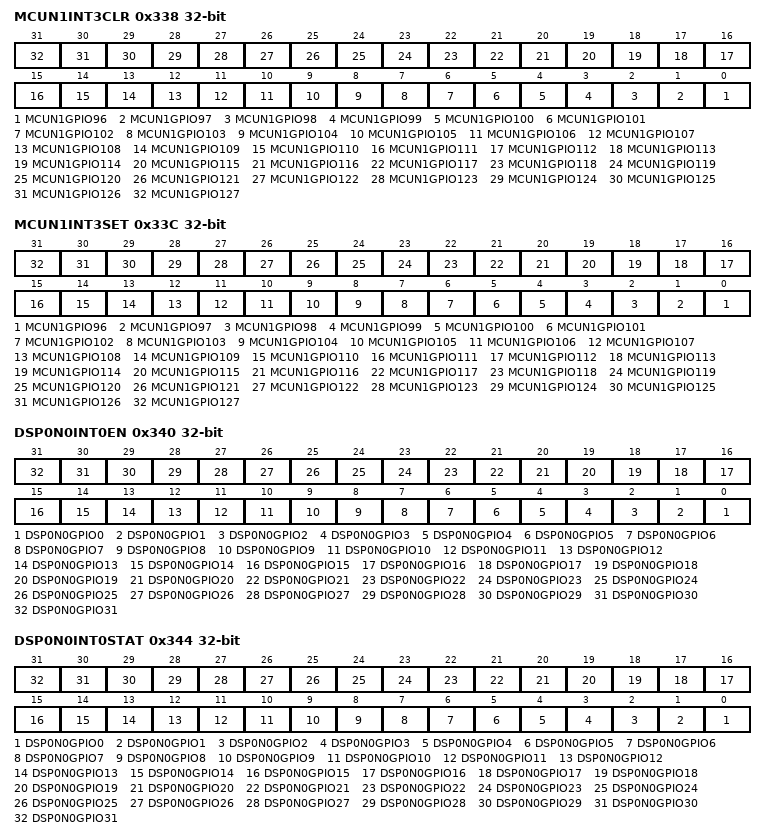
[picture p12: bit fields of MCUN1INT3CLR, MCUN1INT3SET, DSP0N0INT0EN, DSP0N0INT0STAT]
0x338 MCUN1INT3CLR — Write a 1 to a bit in this register to clear the interrupt status associated with that bit.
  [n-96] MCUN1GPIO{n} (n=96..127) — GPIO{n} MCU N1-priority interrupt.
0x33C MCUN1INT3SET — Write a 1 to a bit in this register to instantly generate an interrupt from this module. (Generally used for testing purposes).
  [n-96] MCUN1GPIO{n} (n=96..127) — GPIO{n} MCU N1-priority interrupt.
0x340 DSP0N0INT0EN — Set bits in this register to allow this module to generate the corresponding interrupt.
  [n] DSP0N0GPIO{n} (n=0..31) — GPIO{n} DSP0 N0-priority interrupt.
0x344 DSP0N0INT0STAT — Read bits from this register to discover the cause of a recent interrupt.
  [n] DSP0N0GPIO{n} (n=0..31) — GPIO{n} DSP0 N0-priority interrupt.
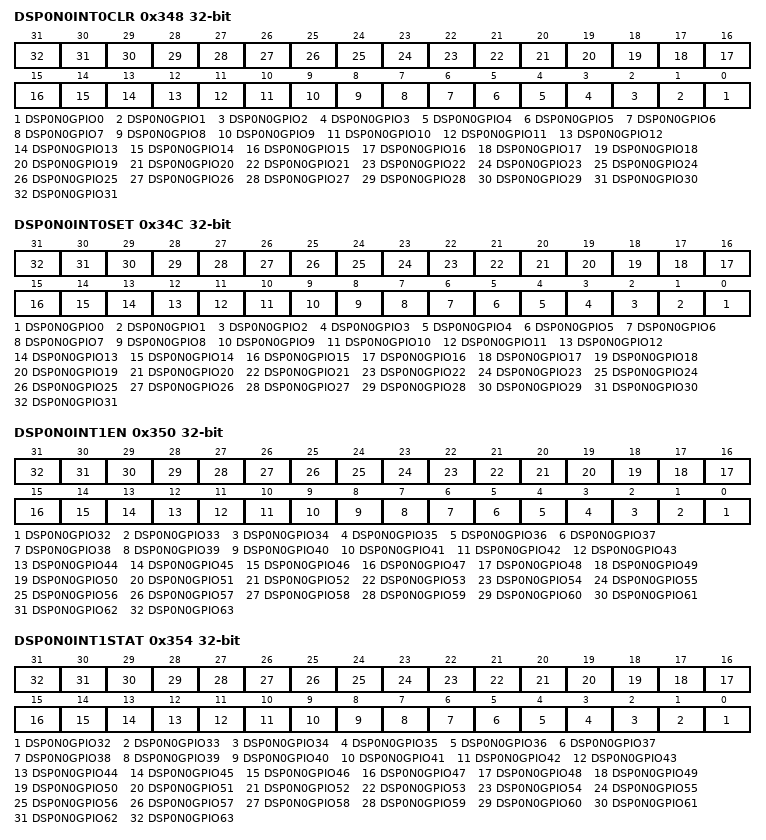
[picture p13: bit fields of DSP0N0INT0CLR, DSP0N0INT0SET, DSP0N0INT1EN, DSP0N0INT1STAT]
0x348 DSP0N0INT0CLR — Write a 1 to a bit in this register to clear the interrupt status associated with that bit.
  [n] DSP0N0GPIO{n} (n=0..31) — GPIO{n} DSP0 N0-priority interrupt.
0x34C DSP0N0INT0SET — Write a 1 to a bit in this register to instantly generate an interrupt from this module. (Generally used for testing purposes).
  [n] DSP0N0GPIO{n} (n=0..31) — GPIO{n} DSP0 N0-priority interrupt.
0x350 DSP0N0INT1EN — Set bits in this register to allow this module to generate the corresponding interrupt.
  [n-32] DSP0N0GPIO{n} (n=32..63) — GPIO{n} DSP0 N0-priority interrupt.
0x354 DSP0N0INT1STAT — Read bits from this register to discover the cause of a recent interrupt.
  fields as DSP0N0INT1EN
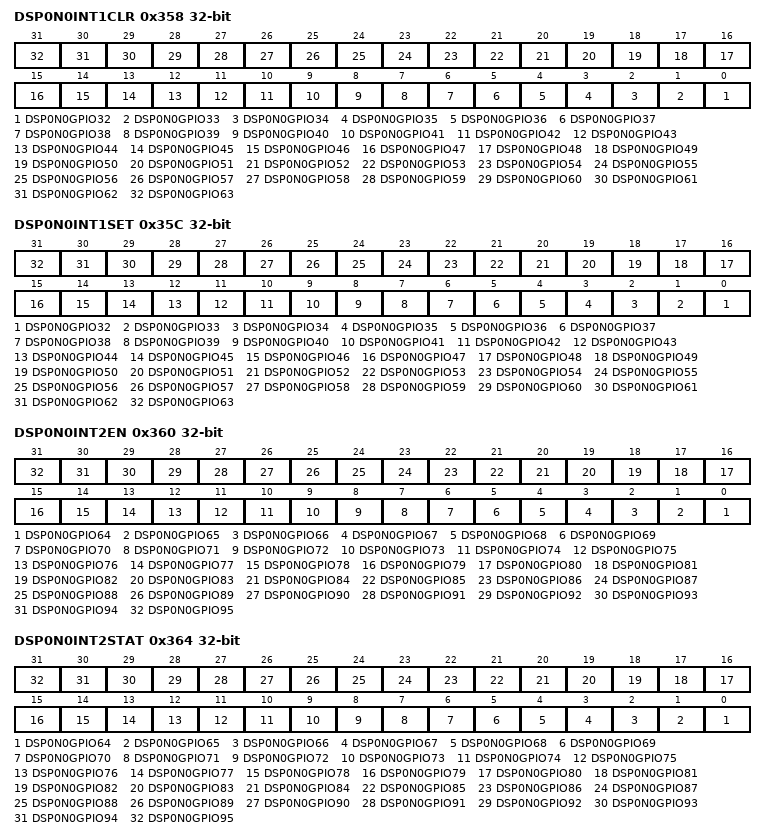
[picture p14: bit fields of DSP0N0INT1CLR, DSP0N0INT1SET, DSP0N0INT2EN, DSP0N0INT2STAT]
0x358 DSP0N0INT1CLR — Write a 1 to a bit in this register to clear the interrupt status associated with that bit.
  fields as DSP0N0INT1EN
0x35C DSP0N0INT1SET — Write a 1 to a bit in this register to instantly generate an interrupt from this module. (Generally used for testing purposes).
  fields as DSP0N0INT1EN
0x360 DSP0N0INT2EN — Set bits in this register to allow this module to generate the corresponding interrupt.
  [n-64] DSP0N0GPIO{n} (n=64..95) — GPIO{n} DSP0 N0-priority interrupt.
0x364 DSP0N0INT2STAT — Read bits from this register to discover the cause of a recent interrupt.
  fields as DSP0N0INT2EN
0x368 DSP0N0INT2CLR — Write a 1 to a bit in this register to clear the interrupt status associated with that bit.
  fields as DSP0N0INT2EN
0x36C DSP0N0INT2SET — Write a 1 to a bit in this register to instantly generate an interrupt from this module. (Generally used for testing purposes).
  fields as DSP0N0INT2EN
0x370 DSP0N0INT3EN — Set bits in this register to allow this module to generate the corresponding interrupt.
  [n-96] DSP0N0GPIO{n} (n=96..127) — GPIO{n} DSP0 N0-priority interrupt.
0x374 DSP0N0INT3STAT — Read bits from this register to discover the cause of a recent interrupt.
  fields as DSP0N0INT3EN
0x378 DSP0N0INT3CLR — Write a 1 to a bit in this register to clear the interrupt status associated with that bit.
  fields as DSP0N0INT3EN
0x37C DSP0N0INT3SET — Write a 1 to a bit in this register to instantly generate an interrupt from this module. (Generally used for testing purposes).
  fields as DSP0N0INT3EN
0x380 DSP0N1INT0EN — Set bits in this register to allow this module to generate the corresponding interrupt.
  [n] DSP0N1GPIO{n} (n=0..31) — GPIO{n} DSP0 N1-priority interrupt.
0x384 DSP0N1INT0STAT — Read bits from this register to discover the cause of a recent interrupt.
  [n] DSP0N1GPIO{n} (n=0..31) — GPIO{n} DSP0 N1-priority interrupt.
0x388 DSP0N1INT0CLR — Write a 1 to a bit in this register to clear the interrupt status associated with that bit.
  [n] DSP0N1GPIO{n} (n=0..31) — GPIO{n} DSP0 N1-priority interrupt.
0x38C DSP0N1INT0SET — Write a 1 to a bit in this register to instantly generate an interrupt from this module. (Generally used for testing purposes).
  [n] DSP0N1GPIO{n} (n=0..31) — GPIO{n} DSP0 N1-priority interrupt.
0x390 DSP0N1INT1EN — Set bits in this register to allow this module to generate the corresponding interrupt.
  [n-32] DSP0N1GPIO{n} (n=32..63) — GPIO{n} DSP0 N1-priority interrupt.
0x394 DSP0N1INT1STAT — Read bits from this register to discover the cause of a recent interrupt.
  fields as DSP0N1INT1EN
0x398 DSP0N1INT1CLR — Write a 1 to a bit in this register to clear the interrupt status associated with that bit.
  fields as DSP0N1INT1EN
0x39C DSP0N1INT1SET — Write a 1 to a bit in this register to instantly generate an interrupt from this module. (Generally used for testing purposes).
  fields as DSP0N1INT1EN
0x3A0 DSP0N1INT2EN — Set bits in this register to allow this module to generate the corresponding interrupt.
  [n-64] DSP0N1GPIO{n} (n=64..95) — GPIO{n} DSP0 N1-priority interrupt.
0x3A4 DSP0N1INT2STAT — Read bits from this register to discover the cause of a recent interrupt.
  fields as DSP0N1INT2EN
0x3A8 DSP0N1INT2CLR — Write a 1 to a bit in this register to clear the interrupt status associated with that bit.
  fields as DSP0N1INT2EN
0x3AC DSP0N1INT2SET — Write a 1 to a bit in this register to instantly generate an interrupt from this module. (Generally used for testing purposes).
  fields as DSP0N1INT2EN
0x3B0 DSP0N1INT3EN — Set bits in this register to allow this module to generate the corresponding interrupt.
  [n-96] DSP0N1GPIO{n} (n=96..127) — GPIO{n} DSP0 N1-priority interrupt.
0x3B4 DSP0N1INT3STAT — Read bits from this register to discover the cause of a recent interrupt.
  fields as DSP0N1INT3EN
0x3B8 DSP0N1INT3CLR — Write a 1 to a bit in this register to clear the interrupt status associated with that bit.
  fields as DSP0N1INT3EN
0x3BC DSP0N1INT3SET — Write a 1 to a bit in this register to instantly generate an interrupt from this module. (Generally used for testing purposes).
  fields as DSP0N1INT3EN
0x3C0 DSP1N0INT0EN — Set bits in this register to allow this module to generate the corresponding interrupt.
  [n] DSP1N0GPIO{n} (n=0..31) — GPIO{n} DSP1 N0-priority interrupt.
0x3C4 DSP1N0INT0STAT — Read bits from this register to discover the cause of a recent interrupt.
  [n] DSP1N0GPIO{n} (n=0..31) — GPIO{n} DSP1 N0-priority interrupt.
0x3C8 DSP1N0INT0CLR — Write a 1 to a bit in this register to clear the interrupt status associated with that bit.
  [n] DSP1N0GPIO{n} (n=0..31) — GPIO{n} DSP1 N0-priority interrupt.
0x3CC DSP1N0INT0SET — Write a 1 to a bit in this register to instantly generate an interrupt from this module. (Generally used for testing purposes).
  [n] DSP1N0GPIO{n} (n=0..31) — GPIO{n} DSP1 N0-priority interrupt.
0x3D0 DSP1N0INT1EN — Set bits in this register to allow this module to generate the corresponding interrupt.
  [n-32] DSP1N0GPIO{n} (n=32..63) — GPIO{n} DSP1 N0-priority interrupt.
0x3D4 DSP1N0INT1STAT — Read bits from this register to discover the cause of a recent interrupt.
  fields as DSP1N0INT1EN
0x3D8 DSP1N0INT1CLR — Write a 1 to a bit in this register to clear the interrupt status associated with that bit.
  fields as DSP1N0INT1EN
0x3DC DSP1N0INT1SET — Write a 1 to a bit in this register to instantly generate an interrupt from this module. (Generally used for testing purposes).
  fields as DSP1N0INT1EN
0x3E0 DSP1N0INT2EN — Set bits in this register to allow this module to generate the corresponding interrupt.
  [n-64] DSP1N0GPIO{n} (n=64..95) — GPIO{n} DSP1 N0-priority interrupt.
0x3E4 DSP1N0INT2STAT — Read bits from this register to discover the cause of a recent interrupt.
  fields as DSP1N0INT2EN
0x3E8 DSP1N0INT2CLR — Write a 1 to a bit in this register to clear the interrupt status associated with that bit.
  fields as DSP1N0INT2EN
0x3EC DSP1N0INT2SET — Write a 1 to a bit in this register to instantly generate an interrupt from this module. (Generally used for testing purposes).
  fields as DSP1N0INT2EN
0x3F0 DSP1N0INT3EN — Set bits in this register to allow this module to generate the corresponding interrupt.
  [n-96] DSP1N0GPIO{n} (n=96..127) — GPIO{n} DSP1 N0-priority interrupt.
0x3F4 DSP1N0INT3STAT — Read bits from this register to discover the cause of a recent interrupt.
  fields as DSP1N0INT3EN
0x3F8 DSP1N0INT3CLR — Write a 1 to a bit in this register to clear the interrupt status associated with that bit.
  fields as DSP1N0INT3EN
0x3FC DSP1N0INT3SET — Write a 1 to a bit in this register to instantly generate an interrupt from this module. (Generally used for testing purposes).
  fields as DSP1N0INT3EN
0x400 DSP1N1INT0EN — Set bits in this register to allow this module to generate the corresponding interrupt.
  [n] DSP1N1GPIO{n} (n=0..31) — GPIO{n} DSP1 N1-priority interrupt.
0x404 DSP1N1INT0STAT — Read bits from this register to discover the cause of a recent interrupt.
  [n] DSP1N1GPIO{n} (n=0..31) — GPIO{n} DSP1 N1-priority interrupt.
0x408 DSP1N1INT0CLR — Write a 1 to a bit in this register to clear the interrupt status associated with that bit.
  [n] DSP1N1GPIO{n} (n=0..31) — GPIO{n} DSP1 N1-priority interrupt.
0x40C DSP1N1INT0SET — Write a 1 to a bit in this register to instantly generate an interrupt from this module. (Generally used for testing purposes).
  [n] DSP1N1GPIO{n} (n=0..31) — GPIO{n} DSP1 N1-priority interrupt.
0x410 DSP1N1INT1EN — Set bits in this register to allow this module to generate the corresponding interrupt.
  [n-32] DSP1N1GPIO{n} (n=32..63) — GPIO{n} DSP1 N1-priority interrupt.
0x414 DSP1N1INT1STAT — Read bits from this register to discover the cause of a recent interrupt.
  fields as DSP1N1INT1EN
0x418 DSP1N1INT1CLR — Write a 1 to a bit in this register to clear the interrupt status associated with that bit.
  fields as DSP1N1INT1EN
0x41C DSP1N1INT1SET — Write a 1 to a bit in this register to instantly generate an interrupt from this module. (Generally used for testing purposes).
  fields as DSP1N1INT1EN
0x420 DSP1N1INT2EN — Set bits in this register to allow this module to generate the corresponding interrupt.
  [n-64] DSP1N1GPIO{n} (n=64..95) — GPIO{n} DSP1 N1-priority interrupt.
0x424 DSP1N1INT2STAT — Read bits from this register to discover the cause of a recent interrupt.
  fields as DSP1N1INT2EN
0x428 DSP1N1INT2CLR — Write a 1 to a bit in this register to clear the interrupt status associated with that bit.
  fields as DSP1N1INT2EN
0x42C DSP1N1INT2SET — Write a 1 to a bit in this register to instantly generate an interrupt from this module. (Generally used for testing purposes).
  fields as DSP1N1INT2EN
0x430 DSP1N1INT3EN — Set bits in this register to allow this module to generate the corresponding interrupt.
  [n-96] DSP1N1GPIO{n} (n=96..127) — GPIO{n} DSP1 N1-priority interrupt.
0x434 DSP1N1INT3STAT — Read bits from this register to discover the cause of a recent interrupt.
  fields as DSP1N1INT3EN
0x438 DSP1N1INT3CLR — Write a 1 to a bit in this register to clear the interrupt status associated with that bit.
  fields as DSP1N1INT3EN
0x43C DSP1N1INT3SET — Write a 1 to a bit in this register to instantly generate an interrupt from this module. (Generally used for testing purposes).
  fields as DSP1N1INT3EN
